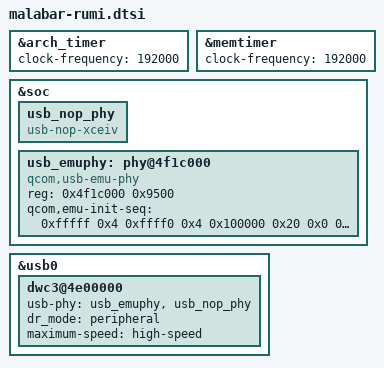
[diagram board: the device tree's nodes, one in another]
// SPDX-License-Identifier: BSD-3-Clause
/*
 * Copyright (c) Qualcomm Technologies, Inc. and/or its subsidiaries.
 */
&arch_timer {
	clock-frequency = <192000>;
};

&memtimer {
	clock-frequency = <192000>;
};

&soc {
	usb_nop_phy: usb_nop_phy {
		compatible = "usb-nop-xceiv";
	};

	usb_emuphy: phy@4f1c000 {
		compatible = "qcom,usb-emu-phy";
		reg = <0x4f1c000 0x9500>;

		qcom,emu-init-seq = <0xfffff 0x4
			0xffff0 0x4
			0x100000 0x20
			0x0 0x20
			0x000101F0 0x20
			0x00100000 0x3c
			0x0 0x3c
			0x0 0x4>;
	};
};

&usb0 {
	dwc3@4e00000 {
		usb-phy = <&usb_emuphy>, <&usb_nop_phy>;
		dr_mode = "peripheral";
		maximum-speed = "high-speed";
	};
};
